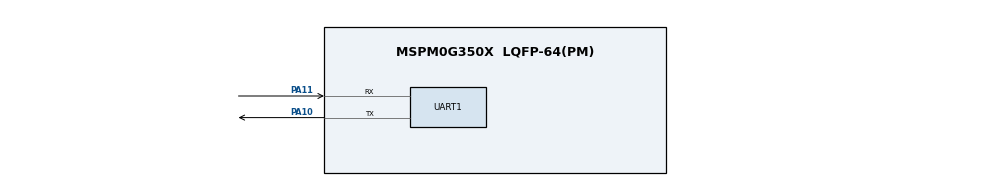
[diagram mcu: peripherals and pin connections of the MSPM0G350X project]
/**
 * @cliArgs --device "MSPM0G350X" --part "Default" --package "LQFP-64(PM)" --product "mspm0_sdk@2.05.01.01"
 * @versions {"tool":"1.21.0+3721"}
 */

/**
 * Import the modules used in this configuration.
 */
const GPIO   = scripting.addModule("/ti/driverlib/GPIO", {}, false);
const GPIO1  = GPIO.addInstance();
const SYSCTL = scripting.addModule("/ti/driverlib/SYSCTL");
const TIMER  = scripting.addModule("/ti/driverlib/TIMER", {}, false);
const TIMER1 = TIMER.addInstance();
const UART   = scripting.addModule("/ti/driverlib/UART", {}, false);
const UART1  = UART.addInstance();

/**
 * Write custom configuration values to the imported modules.
 */
const divider6       = system.clockTree["PLL_CLK2X_DIV"];
divider6.divideValue = 4;

const divider7       = system.clockTree["PLL_PDIV"];
divider7.divideValue = 2;

const divider9       = system.clockTree["UDIV"];
divider9.divideValue = 2;

const gate7  = system.clockTree["MFCLKGATE"];
gate7.enable = true;

const gate8  = system.clockTree["MFPCLKGATE"];
gate8.enable = true;

const multiplier2         = system.clockTree["PLL_QDIV"];
multiplier2.multiplyValue = 10;

const mux8       = system.clockTree["HSCLKMUX"];
mux8.inputSelect = "HSCLKMUX_SYSPLL2X";

GPIO1.$name                         = "GPIO_LEDS";
GPIO1.port                          = "PORTB";
GPIO1.associatedPins[0].assignedPin = "22";
GPIO1.associatedPins[0].$name       = "USER_LED";

const Board = scripting.addModule("/ti/driverlib/Board", {}, false);

SYSCTL.forceDefaultClkConfig = true;
SYSCTL.clockTreeEn           = true;
scripting.suppress("For best practices when the CPUCLK is running at 32MHz and above, clear the flash status bit using DL_FlashCTL_executeClearStatus\\(\\) before executing any flash operation\\. Otherwise there may be false positives\\.", SYSCTL);

TIMER1.interrupts         = ["ZERO"];
TIMER1.timerMode          = "PERIODIC";
TIMER1.timerPeriod        = "1 ms";
TIMER1.$name              = "TIMER_Delay";
TIMER1.timerStartTimer    = true;
TIMER1.peripheral.$assign = "TIMG0";

UART1.$name                    = "UART_0";
UART1.peripheral.rxPin.$assign = "PA11";
UART1.peripheral.txPin.$assign = "PA10";
UART1.txPinConfig.$name        = "ti_driverlib_gpio_GPIOPinGeneric0";
UART1.rxPinConfig.$name        = "ti_driverlib_gpio_GPIOPinGeneric1";

/**
 * Pinmux solution for unlocked pins/peripherals. This ensures that minor changes to the automatic solver in a future
 * version of the tool will not impact the pinmux you originally saw.  These lines can be completely deleted in order to
 * re-solve from scratch.
 */
GPIO1.associatedPins[0].pin.$suggestSolution = "PB22";
Board.peripheral.$suggestSolution            = "DEBUGSS";
Board.peripheral.swclkPin.$suggestSolution   = "PA20";
Board.peripheral.swdioPin.$suggestSolution   = "PA19";
UART1.peripheral.$suggestSolution            = "UART0";
